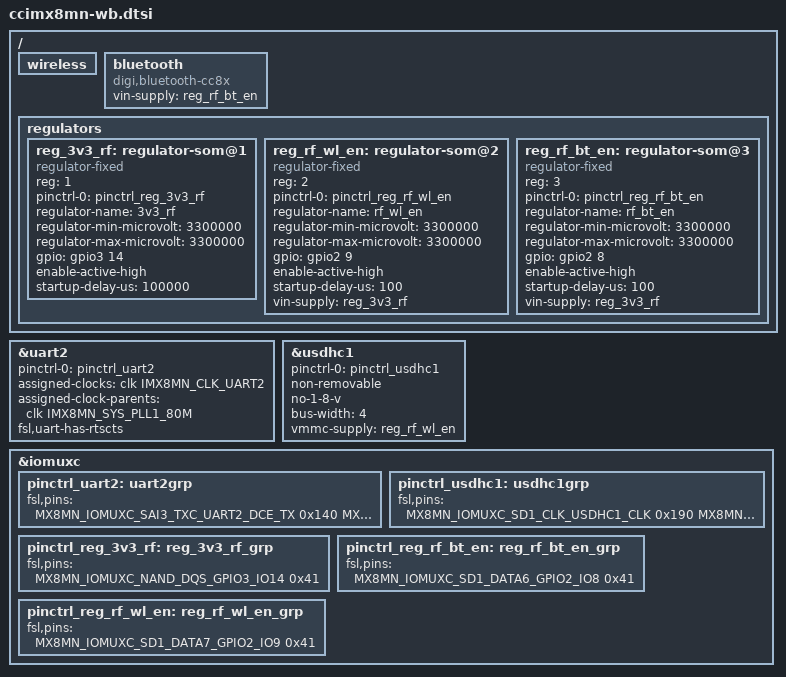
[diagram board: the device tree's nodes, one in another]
/*
 * Copyright 2019, Digi International Inc.
 *
 * Permission to use, copy, modify, and/or distribute this software for any
 * purpose with or without fee is hereby granted, provided that the above
 * copyright notice and this permission notice appear in all copies.
 * THE SOFTWARE IS PROVIDED "AS IS" AND THE AUTHOR DISCLAIMS ALL WARRANTIES
 * WITH REGARD TO THIS SOFTWARE INCLUDING ALL IMPLIED WARRANTIES OF
 * MERCHANTABILITY AND FITNESS. IN NO EVENT SHALL THE AUTHOR BE LIABLE FOR
 * ANY SPECIAL, DIRECT, INDIRECT, OR CONSEQUENTIAL DAMAGES OR ANY DAMAGES
 * WHATSOEVER RESULTING FROM LOSS OF USE, DATA OR PROFITS, WHETHER IN AN
 * ACTION OF CONTRACT, NEGLIGENCE OR OTHER TORTIOUS ACTION, ARISING OUT OF
 * OR IN CONNECTION WITH THE USE OR PERFORMANCE OF THIS SOFTWARE.
 */

 /* Digi ConnectCore 8M Nano (common) */
 #include "ccimx8mn.dtsi"

/ {
	wireless {
		/* U-Boot will fill in the MAC address here */
	};

	bluetooth: bluetooth {
		/* U-Boot will fill in the MAC address here */
		compatible = "digi,bluetooth-cc8x";
		status = "okay";
		vin-supply = <&reg_rf_bt_en>;
	};

	regulators {
		reg_3v3_rf: regulator-som@1 {
			compatible = "regulator-fixed";
			reg = <1>;
			pinctrl-names = "default";
			pinctrl-0 = <&pinctrl_reg_3v3_rf>;
			regulator-name = "3v3_rf";
			regulator-min-microvolt = <3300000>;
			regulator-max-microvolt = <3300000>;
			gpio = <&gpio3 14 GPIO_ACTIVE_HIGH>; /* 3V3_RF_EN */
			enable-active-high;
			startup-delay-us = <100000>;
		};

		reg_rf_wl_en: regulator-som@2 {
			compatible = "regulator-fixed";
			reg = <2>;
			pinctrl-names = "default";
			pinctrl-0 = <&pinctrl_reg_rf_wl_en>;
			regulator-name = "rf_wl_en";
			regulator-min-microvolt = <3300000>;
			regulator-max-microvolt = <3300000>;
			gpio = <&gpio2 9 GPIO_ACTIVE_HIGH>; /* WL_EN */
			enable-active-high;
			startup-delay-us = <100>;
			vin-supply = <&reg_3v3_rf>;
		};

		reg_rf_bt_en: regulator-som@3 {
			compatible = "regulator-fixed";
			reg = <3>;
			pinctrl-names = "default";
			pinctrl-0 = <&pinctrl_reg_rf_bt_en>;
			regulator-name = "rf_bt_en";
			regulator-min-microvolt = <3300000>;
			regulator-max-microvolt = <3300000>;
			gpio = <&gpio2 8 GPIO_ACTIVE_HIGH>; /* BT_EN */
			enable-active-high;
			startup-delay-us = <100>;
			vin-supply = <&reg_3v3_rf>;
		};
	};
};

/* UART2 (Bluetooth) */
&uart2 {
	pinctrl-names = "default";
	pinctrl-0 = <&pinctrl_uart2>;
	assigned-clocks = <&clk IMX8MN_CLK_UART2>;
	assigned-clock-parents = <&clk IMX8MN_SYS_PLL1_80M>;
	fsl,uart-has-rtscts;
	status = "okay";
};

/* USDHC1 (Wireless) */
&usdhc1 {
	pinctrl-names = "default", "sleep";
	pinctrl-0 = <&pinctrl_usdhc1>;
	non-removable;
	no-1-8-v;
	bus-width = <4>;
	vmmc-supply = <&reg_rf_wl_en>;
	status = "okay";
};

/* IOMUX */
&iomuxc {
	/* UART2 (Bluetooth) */
	pinctrl_uart2: uart2grp {
		fsl,pins = <
			MX8MN_IOMUXC_SAI3_TXC_UART2_DCE_TX		0x140
			MX8MN_IOMUXC_SAI3_TXFS_UART2_DCE_RX		0x140
			MX8MN_IOMUXC_SAI3_RXD_UART2_DCE_RTS_B	0x140
			MX8MN_IOMUXC_SAI3_RXC_UART2_DCE_CTS_B	0x140
		>;
	};

	/* USDHC1 (Wireless) */
	pinctrl_usdhc1: usdhc1grp {
		fsl,pins = <
			MX8MN_IOMUXC_SD1_CLK_USDHC1_CLK		0x190
			MX8MN_IOMUXC_SD1_CMD_USDHC1_CMD		0x1d0
			MX8MN_IOMUXC_SD1_DATA0_USDHC1_DATA0	0x1d0
			MX8MN_IOMUXC_SD1_DATA1_USDHC1_DATA1	0x1d0
			MX8MN_IOMUXC_SD1_DATA2_USDHC1_DATA2	0x1d0
			MX8MN_IOMUXC_SD1_DATA3_USDHC1_DATA3	0x1d0
		>;
	};

	pinctrl_reg_3v3_rf: reg_3v3_rf_grp {
		fsl,pins = <
			/* Voltage for RF domain (3V3_RF_EN) */
			MX8MN_IOMUXC_NAND_DQS_GPIO3_IO14		0x41
		>;
	};

	pinctrl_reg_rf_bt_en: reg_rf_bt_en_grp {
		fsl,pins = <
			/* Bluetooth enable (BT_EN) */
			MX8MN_IOMUXC_SD1_DATA6_GPIO2_IO8		0x41
		>;
	};

	pinctrl_reg_rf_wl_en: reg_rf_wl_en_grp {
		fsl,pins = <
			/* Wireless enable (WL_EN) */
			MX8MN_IOMUXC_SD1_DATA7_GPIO2_IO9		0x41
		>;
	};
};
